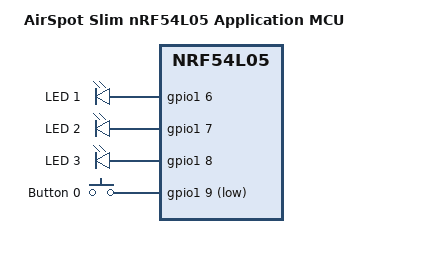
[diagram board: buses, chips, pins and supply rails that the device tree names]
/*
 * Copyright (c) 2025 AirSpot
 *
 * SPDX-License-Identifier: Apache-2.0
 */

/dts-v1/;

#include <nordic/nrf54l05_cpuapp.dtsi>

/ {
	compatible = "airspot,airspot_slim_nrf54l05-cpuapp";
	model = "AirSpot Slim nRF54L05 Application MCU";

	chosen {
		zephyr,code-partition = &slot0_partition;
		zephyr,sram = &cpuapp_sram;
	};

	aliases {
		sw0 = &button0;
	};

	/* LED definitions - from schematic Sheet 5 (nRF54L05) */
	/* Note: These are RGB LED control pins, not individual LEDs */
	leds: leds {
		compatible = "gpio-leds";
		led0: led_0 {
			/* NRF_UI_LED_1 - P1.06/ASO0/AIN2 */
			gpios = <&gpio1 6 GPIO_ACTIVE_HIGH>;
			label = "LED 1";
		};
		led1: led_1 {
			/* NRF_UI_LED_2 - P1.07/ASI1/AIN3 */
			gpios = <&gpio1 7 GPIO_ACTIVE_HIGH>;
			label = "LED 2";
		};
		led2: led_2 {
			/* NRF_UI_LED_3 - P1.08/CLKOUTFAST/EXTREF */
			gpios = <&gpio1 8 GPIO_ACTIVE_HIGH>;
			label = "LED 3";
		};
	};

	/* Button definition - from schematic Sheet 5 (nRF54L05) */
	buttons {
		compatible = "gpio-keys";
		button0: button_0 {
			/* NRF_UI_nBTN_1 - P1.09/ASO2/RADIO0 */
			/* Active low (nBTN = not Button) */
			gpios = <&gpio1 9 (GPIO_PULL_UP | GPIO_ACTIVE_LOW)>;
			label = "Button 0";
			zephyr,code = <INPUT_KEY_0>;
		};
	};
};

/* FLPR not supported yet, give all SRAM and RRAM to the APP core */
&cpuapp_sram {
	reg = <0x20000000 DT_SIZE_K(96)>;
	ranges = <0x0 0x20000000 DT_SIZE_K(96)>;
	status = "okay";
};

/* Enable GPIO ports */
&gpio0 {
	status = "okay";
};

&gpio1 {
	status = "okay";
};

&gpio2 {
	status = "okay";
};

/* Include default memory partition configuration file */
#include <nordic/nrf54l05_partition.dtsi>

